# AE302F80F5582AE_CM55_HE_View register map
Vendor: Alif Semiconductor; Series: E3; File version: 1.0
CPU: CM55 r1p0, selectable endian, MPU, FPU, double-precision FPU, DSP, VTOR, 8 interrupt priority bits, 1 SAU regions
Registers are 32-bit, read-write, reset 0x0 unless marked. A register's access mark holds for its fields unless they carry their own. Offsets are from the block's base; [hi:lo] are bit positions; {n}, {i} and the like mark numbered series; <NAME> marks a mode.

## ETH (part 1 of 3)
Base 0x48100000
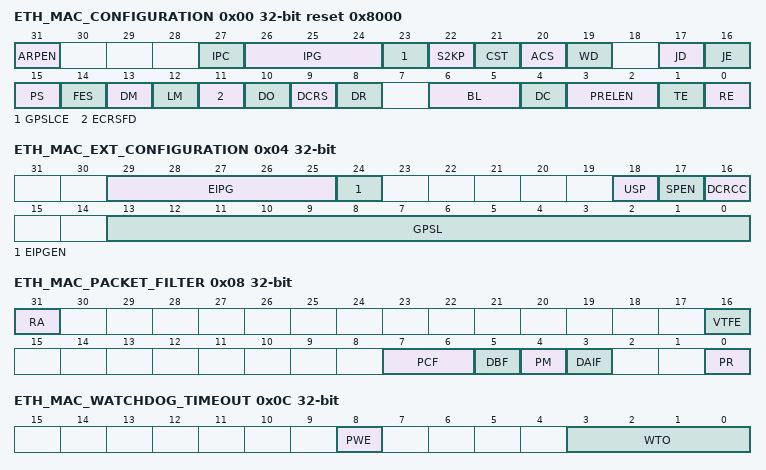
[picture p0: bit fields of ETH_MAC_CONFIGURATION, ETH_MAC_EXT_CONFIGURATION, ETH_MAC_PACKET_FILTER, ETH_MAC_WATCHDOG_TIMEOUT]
0x00 ETH_MAC_CONFIGURATION reset 0x8000 — MAC Configuration Register
  [31] ARPEN — ARP Offload Enable When this bit is set, the MAC can recognize an incoming ARP request packet and schedules the ARP packet for transmission. It forwards the ARP packet to the application and also indicate the events in the RxStatus. When this bit is reset, the MAC receiver does not recognize any ARP packet and indicates them as Type frame in the RxStatus. This bit is available only when the Enable IPv4 ARP Offload is selected.
    0=ARP offload is disabled; 1=ARP offload is enabled
  [27] IPC — Checksum Offload When set, this bit enables the IPv4 header checksum checking and IPv4 or IPv6 TCP, UDP, or ICMP payload checksum checking. When this bit is reset, the COE function in the receiver is disabled.
    0=IP header/payload checksum checking is disabled; 1=IP header/payload checksum checking is enabled
  [26:24] IPG — Inter-Packet Gap These bits control the minimum IPG between packets during transmission. This range of minimum IPG is valid in full-duplex mode. In the half-duplex mode, the minimum IPG can be configured only for 64-bit times (IPG = 100). Lower values are not considered. When a JAM pattern is being transmitted because of backpressure activation, the MAC does not consider the minimum IPG. This above function (IPG less than 96-bit times) is valid only when the ETH_MAC_EXT_CONFIGURATION[EIPGEN] bit is reset. When EIPGEN is set, then the minimum IPG (greater than 96-bit times) is controlled as per the description given in the ETH_MAC_EXT_CONFIGURATION[EIPG] field.
    0=96-bit times IPG; 1=88-bit times IPG; 2=80-bit times IPG; 3=72-bit times IPG; 4=64-bit times IPG; 5=56-bit times IPG; 6=48-bit times IPG; 7=40-bit times IPG
  [23] GPSLCE — Giant Packet Size Limit Control Enable When this bit is set, the MAC considers the value in the ETH_MAC_EXT_CONFIGURATION[GPSL] field to declare a received packet as Giant packet. This field must be programmed to more than 1,518 bytes. Otherwise, the MAC considers 1,518 bytes as giant packet limit. When this bit is reset, the MAC considers a received packet as Giant packet when its size is greater than 1,518 bytes (1522 bytes for tagged packet). The watchdog timeout limit, Jumbo Packet Enable and 2KB Packet Enable have higher precedence over this bit, that is the MAC considers a received packet as Giant packet when its size is greater than 9,018 bytes (9,022 bytes for tagged packet) with Jumbo Packet Enabled and greater than 2,000 bytes with 2KB Packet Enabled. The watchdog timeout, if enabled, terminates the received packet when watchdog limit is reached. Therefore, the programmed giant packet limit must be less than the watchdog limit to get the giant packet status.
    0=Giant packet size limit control is disabled; 1=Giant packet size limit control is enabled
  [22] S2KP — IEEE 802.3as Support for 2KB Packets When this bit is set, the MAC considers all packets with up to 2,000 bytes length as normal packets. When the JE bit is not set, the MAC considers all received packets of size more than 2KB as Giant packets. When this bit is reset and the JE bit is not set, the MAC considers all received packets of size more than 1,518 bytes (1,522 bytes for tagged) as giant packets. Note: When the JE bit is set, setting this bit has no effect on the giant packet status.
    0=Support upto 2KB packet is disabled; 1=Support upto 2KB packet is Enabled
  [21] CST — CRC stripping for Type packets When this bit is set, theMAC strips and drops the last four bytes (FCS) of all Ether type packets, as indicated by the Length/Type field of the packet, before forwarding the packet to the application
    0=CRC stripping for type packets is disabled; 1=CRC stripping for type packets is enabled
  [20] ACS — Automatic Pad or CRC Stripping When this bit is set, the MAC strips the Pad or FCS field on the incoming packets only if the value of the length field is less than 1,536 bytes. All received packets with length field greater than or equal to 1,536 bytes are passed to the application without stripping the Pad or FCS field. When this bit is reset, the MAC passes all incoming packets to the application, without any modification.
    0=Automatic Pad or CRC stripping is disabled; 1=Automatic Pad or CRC stripping is enabled
  [19] WD — Watchdog Disable When this bit is set, the MAC disables the watchdog timer on the receiver. The MAC can receive packets of up to 16,383 bytes. When this bit is reset, the MAC does not allow more than 2,048 bytes (10,240 if JE is set high) of the packet being received. The MAC cuts off any bytes received after 2,048 bytes.
    0=Watchdog is enabled; 1=Watchdog is disabled
  [17] JD — Jabber Disable When this bit is set, the MAC disables the jabber timer on the transmitter. The MAC can transfer packets of up to 16,383 bytes. When this bit is reset, if the application sends more than 2,048 bytes of data (10,240 if JE is set high) during transmission, the MAC does not send rest of the bytes in that packet.
    0=Jabber is enabled; 1=Jabber is disabled
  [16] JE — Jumbo Packet Enable When this bit is set, the MAC allows jumbo packets of 9,018 bytes (9,022 bytes for VLAN tagged packets) without reporting a giant packet error in the Rx packet status.
    0=Jumbo packet is disabled; 1=Jumbo packet is enabled
  [15] PS ro — Port Select This bit selects the Ethernet line speed. This bit, along with the FES bit, selects the exact line speed. Their value is also reflected in the ETH_STAT0[MAC_SPEED_O] field.
    1=For 10 or 100 Mbps operations
  [14] FES — Speed This bit selects the speed mode. Its value along with the PS bit value is also reflected in the ETH_STAT0[MAC_SPEED_O] field.
    0=10 Mbps; 1=100 Mbps
  [13] DM — Duplex Mode When this bit is set, the MAC operates in the full-duplex mode in which it can transmit and receive simultaneously.
    0=Half-duplex mode; 1=Full-duplex mode
  [12] LM — Loopback Mode When this bit is set, the MAC operates in the loopback mode at RMII.
    0=Loopback is disabled; 1=Loopback is enabled
  [11] ECRSFD — Enable Carrier Sense Before Transmission in Full-Duplex Mode When this bit is set, the MAC transmitter checks the ETH_CRS_DV signal before packet transmission in the full-duplex mode. The MAC starts the transmission only when the ETH_CRS_DV signal is low. When this bit is reset, the MAC transmitter ignores the status of the ETH_CRS_DV signal.
    0=ECRSFD is disabled; 1=ECRSFD is enabled
  [10] DO — Disable Receive Own When this bit is set, the MAC disables the reception of packets when the ETH_TXEN signal is asserted in the half-duplex mode. When this bit is reset, the MAC receives all packets given by the PHY. This bit is not applicable in the full-duplex mode.
    0=Enable receive own; 1=Disable receive own
  [9] DCRS — Disable Carrier Sense During Transmission When this bit is set, the MAC transmitter ignores the RMII ETH_CRS_DV signal during packet transmission in the half-duplex mode. As a result, no errors are generated because of Loss of Carrier or No Carrier during transmission. When this bit is reset, the MAC transmitter generates errors because of Carrier Sense. The MAC can even abort the transmission.
    0=Enable carrier sense during transmission; 1=Disable carrier sense during transmission
  [8] DR — Disable Retry When this bit is set, the MAC attempts only one transmission. When a collision occurs on the RMII interface, the MAC ignores the current packet transmission and reports a Packet Abort with excessive collision error in the Tx packet status. When this bit is reset, the MAC retries based on the settings of the BL field. This bit is applicable only in the half-duplex mode.
    0=Enable retry; 1=Disable retry
  [6:5] BL — Back-Off Limit The back-off limit determines the random integer number (r) of slot time delays (512-bit times) for which the MAC waits before rescheduling a transmission attempt during retries after a collision.n = retransmission attempt. The random integer r takes the value in the range 0 <= r < 2^k This bit is applicable only in the half-duplex mode.
    0=k = min(n, 10); 1=k = min(n, 8); 2=k = min(n, 4); 3=k = min(n, 1)
  [4] DC — Deferral Check When this bit is set, the deferral check function is enabled in the MAC. The MAC issues a Packet Abort status, along with the excessive deferral error bit set in the Tx packet status, when the Tx state machine is deferred for more than 24,288-bit times in 10 or 100 Mbps mode. The defer time is not cumulative. For example, if the transmitter defers for 10,000-bit times because the ETH_CRS_DV signal is active and the ETH_CRS_DV signal becomes inactive, the transmitter transmits and collision happens. Because of collision, the transmitter needs to back off and then defer again after back off completion. In such a scenario, the deferral timer is reset to 0, and it is restarted. When this bit is reset, the deferral check function is disabled and the MAC defers until the ETH_CRS_DV signal goes inactive. This bit is applicable only in the half-duplex mode.
    0=Deferral check function is disabled; 1=Deferral check function is enabled
  [3:2] PRELEN — Preamble Length for Transmit packets These bits control the number of preamble bytes that are added to the beginning of every Tx packet. The preamble reduction occurs only when the MAC is operating in the full-duplex mode.
    0=7 bytes of preamble; 1=5 bytes of preamble; 2=3 bytes of preamble
  [1] TE — Transmitter Enable When this bit is set, the Tx state machine of the MAC is enabled for transmission on the RMII interface. When this bit is reset, the MAC Tx state machine is disabled after it completes the transmission of the current packet. The Tx state machine does not transmit any more packets.
    0=Transmitter is disabled; 1=Transmitter is enabled
  [0] RE — Receiver Enable When this bit is set, the Rx state machine of the MAC is enabled for receiving packets from the RMII interface. When this bit is reset, the MAC Rx state machine is disabled after it completes the reception of the current packet. The Rx state machine does not receive any more packets from the RMII interface.
    0=Receiver is disabled; 1=Receiver is enabled
0x04 ETH_MAC_EXT_CONFIGURATION — MAC Extended Configuration Register
  [29:25] EIPG — Extended Inter-Packet Gap The value in this field is applicable when the EIPGEN bit is set. The five bits of this field are the most significant bits; the ETH_MAC_CONFIGURATION[IPG] field has the three least significant bits. Together, the eight bits represent the value of the minimum IPG greater than 96-bit times, in steps of 8-bit times: {EIPG, IPG}. 0x0: 104-bit times 0x1: 112-bit times 0x2: 120-bit times 0xFF: 2144-bit times
  [24] EIPGEN — Extended Inter-Packet Gap Enable When this bit is set, the MAC uses the EIPG field for the extended inter-packet gap. For details, see the description of the EIPG field. When this bit is reset, the MAC ignores the EIPG field and uses the ETH_MAC_CONFIGURATION[IPG] field as the minimum IPG less than or equal to 96-bit times, in steps of 8-bit times. Note: The extended Inter-Packet Gap feature must be enabled when operating in Full-Duplex mode only. There may be undesirable effects on back-pressure function and frame transmission if it is enabled in Half-Duplex mode.
    0=Extended inter-packet gap is disabled; 1=Extended inter-packet gap is enabled
  [18] USP — Unicast Slow Protocol Packet Detect When this bit is set, the MAC detects the Slow Protocol packets with unicast address of the station specified in the ETH_MAC_ADDRESS0_HIGH and ETH_MAC_ADDRESS0_LOW registers. The MAC also detects the Slow Protocol packets with the Slow Protocols multicast address (01-80-C2-00-00-02). When this bit is reset, the MAC detects only Slow Protocol packets with the Slow Protocol multicast address specified in the IEEE 802.3-2015 Specification, Section
    0=Unicast slow protocol packet detection is disabled; 1=Unicast slow protocol packet detection is enabled
  [17] SPEN — Slow Protocol Detection Enable When this bit is set, MAC processes the Slow Protocol packets (Ether Type 0x8809) and provides the Rx status. The MAC discards the Slow Protocol packets with invalid sub-types. When this bit is reset, the MAC forwards all the error-free Slow Protocol packets to the application. The MAC considers such packets as normal Type packets.
    0=Slow protocol detection is disabled; 1=Slow protocol detection is enabled
  [16] DCRCC — Disable CRC Checking for Received Packets When this bit is set, the MAC receiver does not check the CRC field in the received packets. When this bit is reset, the MAC receiver always checks the CRC field in the received packets.
    0=CRC checking is enabled; 1=CRC checking is disabled
  [13:0] GPSL — Giant Packet Size Limit If the received packet size is greater than the value programmed in this field in units of bytes, the MAC declares the received packet as Giant packet. The value programmed in this field must be greater than or equal to 1,518 bytes. Any other programmed value is considered as 1,518 bytes. For VLAN tagged packets, the MAC adds 4 bytes to the programmed value. When the Enable Double VLAN Processing option is selected, the MAC adds 8 bytes to the programmed value for double VLAN tagged packets. The value in this field is applicable when the GPSLCE bit is set in ETH_MAC_CONFIGURATION register.
0x08 ETH_MAC_PACKET_FILTER — MAC Packet Filter Register
  [31] RA — Receive All When this bit is set, the MAC Receiver module passes all received packets to the application, irrespective of whether they pass the address filter or not. The result of the SA or DA filtering is updated (pass or fail) in the corresponding bit in the Rx Status Word. When this bit is reset, the Receiver module passes only those packets to the application that pass the SA or DA address filter.
    0=Receive all is disabled; 1=Receive all is enabled
  [16] VTFE — VLAN Tag Filter Enable When this bit is set, the MAC drops the VLAN tagged packets that do not match the VLAN Tag. When this bit is reset, the MAC forwards all packets irrespective of the match status of the VLAN Tag.
    0=VLAN tag filter is disabled; 1=VLAN tag filter is enabled
  [7:6] PCF — Pass Control Packets These bits control the forwarding of all control packets (including unicast and multicast Pause packets).
    0=MAC filters all control packets from reaching the application; 1=MAC forwards all control packets except pause packets to the application even if they fail the address filter; 2=MAC forwards all control packets to the application even if they fail the address filter; 3=MAC forwards the control packets that pass the address filter
  [5] DBF — Disable Broadcast Packets When this bit is set, the AFM module blocks all incoming broadcast packets. In addition, it overrides all other filter settings. When this bit is reset, the AFM module passes all received broadcast packets.
    0=Enable broadcast packets; 1=Disable broadcast packets
  [4] PM — Pass All Multicast When this bit is set, it indicates that all the received packets with a multicast destination address (first bit in the destination address field is '1') are passed. When this bit is reset, filtering of multicast packet depends on HMC bit.
    0=Pass all multicast is disabled; 1=Pass all multicast is enabled
  [3] DAIF — DA Inverse Filtering When this bit is set, the Address Check block operates in inverse filtering mode for the DA address comparison for both unicast and multicast packets. When this bit is reset, normal filtering of packets is performed.
    0=DA inverse filtering is disabled; 1=DA inverse filtering is enabled
  [0] PR — Promiscuous Mode When this bit is set, the MAC transfers all incoming packets to the application regardless of the destination or source address filtering status. The MAC clears the SA or DA Filter Fail status bits of the MAC Rx Status Word. When this bit is reset, the MAC transfers to the application only the packets that pass destination or source address filtering.
    0=Promiscuous mode is disabled; 1=Promiscuous mode is enabled
0x0C ETH_MAC_WATCHDOG_TIMEOUT — Watchdog Timeout Register
  [8] PWE — Programmable Watchdog Enable When this bit is set and the ETH_MAC_CONFIGURATION[WD] bit is reset, the WTO field is used as watchdog timeout limit for a received packet. When this bit is cleared, the watchdog timeout for a received packet is controlled by setting of the ETH_MAC_CONFIGURATION[WD] and ETH_MAC_CONFIGURATION[JE] bits.
    0=Programmable watchdog is disabled; 1=Programmable watchdog is enabled
  [3:0] WTO — Watchdog Timeout When the PWE bit is set and the ETH_MAC_CONFIGURATION[WD] bit is reset, this field is used as watchdog timeout limit for a received packet. If the length of a received packet exceeds the value of this field, such packet is terminated and declared as an error packet. Note: When the PWE bit is set, the value in this field must be more than 1,522 (0x5F2). Otherwise, the IEEE 802.3-specified valid tagged packets are declared as error packets and then dropped.
    {v}={v+2}KB (v=0..13); 14=16383 bytes
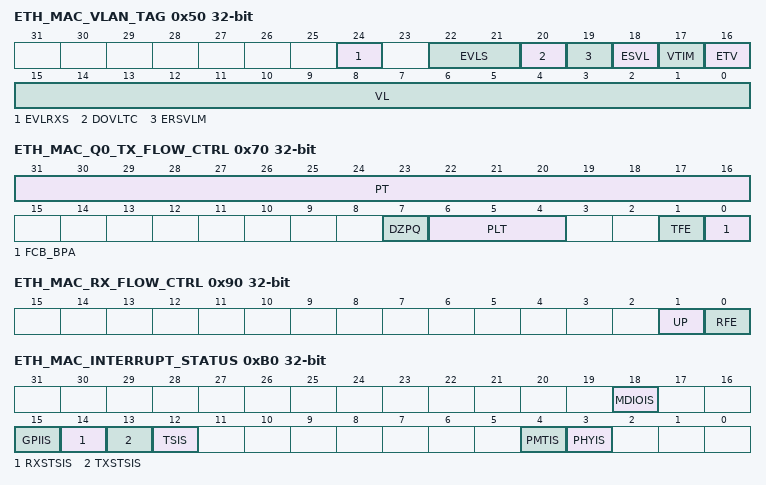
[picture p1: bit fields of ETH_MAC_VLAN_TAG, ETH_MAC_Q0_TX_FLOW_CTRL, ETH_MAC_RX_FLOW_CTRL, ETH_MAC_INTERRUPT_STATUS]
0x50 ETH_MAC_VLAN_TAG — VLAN Tag Register
  [24] EVLRXS — Enable VLAN Tag in Rx status When this bit is set, MAC provides the outer VLAN Tag in the Rx status. When this bit is reset, the MAC does not provide the outer VLAN Tag in Rx status.
    0=VLAN tag in Rx status is disabled; 1=VLAN tag in Rx status is enabled
  [22:21] EVLS — Enable VLAN Tag Stripping on Receive This field indicates the stripping operation on the outer VLAN Tag in the received packet.
    0=Do not strip; 1=Strip if VLAN filter passes; 2=Strip if VLAN filter fails; 3=Always strip
  [20] DOVLTC — Disable VLAN Type Check When this bit is set, the MAC does not check whether the VLAN Tag specified by the ERIVLT bit is of type S-VLAN or C-VLAN. When this bit is reset, the MAC filters or matches the VLAN Tag specified by the ERIVLT bit only when VLAN Tag type is similar to the one specified by the ERSVLM bit. The VLAN filter is bypassed when VLAN Type of received packet do not match the programmed VLAN Type in the VLAN filter.
    0=VLAN type check is enabled; 1=VLAN type check is disabled
  [19] ERSVLM — Enable Receive S-VLAN Match When this bit is set, the MAC receiver enables filtering or matching for S-VLAN (Type = 0x88A8) packets. When this bit is reset, the MAC receiver enables filtering or matching for C-VLAN (Type = 0x8100) packets. The ERIVLT bit determines the VLAN tag position considered for filtering or matching.
    0=Receive S-VLAN match is disabled; 1=Receive S-VLAN match is enabled
  [18] ESVL — Enable S-VLAN When this bit is set, the MAC transmitter and receiver consider the S-VLAN packets (Type = 0x88A8) as valid VLAN tagged packets.
    0=S-VLAN is disabled; 1=S-VLAN is enabled
  [17] VTIM — VLAN Tag Inverse Match Enable When this bit is set, this bit enables the VLAN Tag inverse matching. The packets without matching VLAN Tag are marked as matched. When reset, this bit enables the VLAN Tag perfect matching. The packets with matched VLAN Tag are marked as matched.
    0=VLAN tag inverse match is disabled; 1=VLAN tag inverse match is enabled
  [16] ETV — Enable 12-Bit VLAN Tag Comparison When this bit is set, a 12-bit VLAN identifier is used for comparing and filtering instead of the complete 16-bit VLAN tag. Bits[11-0] of the VLAN tag are compared with the corresponding field in the received VLAN-tagged packet. Similarly, when enabled, only 12 bits of the VLAN tag in the received packet are used for hash-based VLAN filtering. When this bit is reset, all 16 bits of the 15th and 16th bytes of the received VLAN packet are used for comparison and VLAN hash filtering.
    0=12-Bit VLAN tag comparison is disabled; 1=12-Bit VLAN tag comparison is enabled
  [15:0] VL — VLAN Tag Identifier for Receive Packets This field contains the 802.1Q VLAN tag to identify the VLAN packets. This VLAN tag identifier is compared to the 15th and 16th bytes of the packets being received for VLAN packets. The following list describes the bits of this field: Bits[15-13]: User Priority Bit 12: Canonical Format Indicator (CFI) or Drop Eligible Indicator (DEI) Bits[11-0]: VLAN Identifier (VID) field of VLAN tag If this field ([11-0] if ETV is set) is all zeros, the MAC does not check the 15th and 16th bytes for VLAN tag comparison and declares all packets with Type field value of 0x8100 or 0x88A8 as VLAN packets.
0x70 ETH_MAC_Q0_TX_FLOW_CTRL — Flow Control Register
  [31:16] PT — Pause Time This field holds the value to be used in the Pause Time field in the Tx control packet. If the Pause Time bits are configured to be double-synchronized to the RMII clock domain, consecutive writes to this register must be performed only after at least four clock cycles in the destination clock domain.
  [7] DZPQ — Disable Zero-Quanta Pause When this bit is set, it disables the automatic generation of the zero-quanta Pause packets. When this bit is reset, normal operation with automatic zero-quanta Pause packet generation is enabled.
    0=Zero-quanta pause packet generation is enabled; 1=Zero-quanta pause packet generation is disabled
  [6:4] PLT — Pause Low Threshold This field configures the automatic retransmission interval of the Pause packet. The value must always be less than the Pause Time configured in the PT field. For example, if PT = 0x100 (256 slot times), and PLT = 0x1, a second Pause packet is automatically transmitted at 228 (256-28) slot times after the first Pause packet is transmitted. The following list provides the threshold values for different values.The slot time is defined as the time taken to transmit 512 bits (64 bytes) on the RMII interface. This (approximate) computation is based on the packet size (64, 1518, 2000, 9018, 16384, or 32768) + 2 Pause Packet Size + IPG in Slot Times.
    0=Pause time minus 4 slot times (PT - 4 slot times); 1=Pause time minus 28 slot times (PT - 28 slot times); 2=Pause time minus 36 slot times (PT - 36 slot times); 3=Pause time minus 144 slot times (PT - 144 slot times); 4=Pause time minus 256 slot times (PT - 256 slot times); 5=Pause time minus 512 slot times (PT - 512 slot times)
  [1] TFE — Transmit Flow Control Enable Full-Duplex Mode: In the full-duplex mode, when this bit is set, the MAC enables the flow control operation to Tx Pause packets. When this bit is reset, the flow control operation in the MAC is disabled, and the MAC does not transmit any Pause packets. Half-Duplex Mode: In the half-duplex mode, when this bit is set, the MAC enables the backpressure operation. When this bit is reset, the backpressure feature is disabled.
    0=Transmit flow control is disabled; 1=Transmit flow control is enabled
  [0] FCB_BPA — Flow Control Busy or Backpressure Activate This bit initiates a Pause packet in the full-duplex mode and activates the backpressure function in the half-duplex mode if the TFE bit is set. Full-Duplex Mode: In the full-duplex mode, this bit must be read as 0x0 before writing to this register. To initiate a Pause packet, the application must set this bit to 0x1. During Control packet transfer, this bit continues to be set to indicate that a packet transmission is in progress. When Pause packet transmission is complete, the MAC resets this bit to 0x0. The user must not write to this register until this bit is cleared. Half-Duplex Mode: When this bit is set (and TFE bit is set) in the half-duplex mode, the MAC asserts the backpressure. During backpressure, when the MAC receives a new packet, the transmitter starts sending a JAM pattern resulting in a collision. Access restriction applies. - MAC initiates the pause packet or activates the backpressure, when application writes 1. - MAC writes 0 after the operation is complete. - MAC ignores when application writes 0.
    0=Flow control busy or backpressure activate is disabled; 1=Flow control busy or backpressure activate is enabled
0x90 ETH_MAC_RX_FLOW_CTRL — Receive Flow Control Register
  [1] UP — Unicast Pause Packet Detect A pause packet is processed when it has the unique multicast address specified in the IEEE 802.3 Specification. When this bit is set, the MAC can also detect Pause packets with unicast address of the station. This unicast address must be as specified in ETH_MAC_ADDRESS0_HIGH and ETH_MAC_ADDRESS0_LOW. When this bit is reset, the MAC only detects Pause packets with unique multicast address. Note: The MAC does not process a Pause packet if the multicast address is different from the unique multicast address. This is also applicable to the received PFC packet when the Priority Flow Control (PFC) is enabled. The unique multicast address (0x1_80_C2_00_00_01) is as specified in the IEEE 802.1 Qbb-2011 Specification.
    0=Unicast pause packet detect disabled; 1=Unicast pause packet detect enabled
  [0] RFE — Receive Flow Control Enable When this bit is set and the MAC is operating in full-duplex mode, the MAC decodes the received Pause packet and disables its transmitter for a specified (Pause) time. When this bit is reset or the MAC is operating in half-duplex mode, the decode function of the Pause packet is disabled. When PFC is enabled, flow control is enabled for PFC packets. The MAC decodes the received PFC packet and disables the Transmit queue, with matching priorities, for a duration of received Pause time.
    0=Receive flow control is disabled; 1=Receive flow control is enabled
0xB0 ETH_MAC_INTERRUPT_STATUS ro — Interrupt Status Register
  [18] MDIOIS — MDIO Interrupt Status When set, this bit indicates to the application that MDIO operation is complete. MAC writes 0 to this bit when the application reads this bit. Application can write 1 to clear this bit when ETH_MAC_CSR_SW_CTRL[RCWE] = 1. Following access restrictions apply: - Clears on read - Clears on write 1, when ETH_MAC_CSR_SW_CTRL[RCWE] = 1 - Self-set to 1 on internal event
    0=MDIO interrupt status not active; 1=MDIO interrupt status active
  [15] GPIIS — GPI Interrupt Status This bit is set when any active event (LL or LH) occurs on the ETH_MAC_GPIO_STATUS[GPIS] field and the corresponding bit is enabled in the ETH_MAC_GPIO_CONTROL[GPIE] field. This bit is cleared on reading the ETH_MAC_GPIO_STATUS[GPIS] field.
    0=GPI Interrupt status not active; 1=GPI Interrupt status active
  [14] RXSTSIS — Receive Status Interrupt This bit indicates the status of received packets. This bit is set when the RWT bit is set in the ETH_MAC_RX_TX_STATUS register. This bit is cleared when the corresponding interrupt source bit is read (or corresponding interrupt source bit is written to 1 when the ETH_MAC_CSR_SW_CTRL[RCWE] bit is set) in the ETH_MAC_RX_TX_STATUS register.
    0=Receive interrupt status not active; 1=Receive interrupt status active
  [13] TXSTSIS — Transmit Status Interrupt This bit indicates the status of transmitted packets. This bit is set when any of the following bits is set: - ETH_MAC_RX_TX_STATUS[EXCOL] - ETH_MAC_RX_TX_STATUS[LCOL] - ETH_MAC_RX_TX_STATUS[EXDEF] - ETH_MAC_RX_TX_STATUS[LCARR] - ETH_MAC_RX_TX_STATUS[NCARR] - ETH_MAC_RX_TX_STATUS[TJT]
    0=Transmit interrupt status not active; 1=Transmit interrupt status active
  [12] TSIS — Timestamp Interrupt Status This bit is set when any of the following conditions is true: - The ETH_MAC_TIMESTAMP_STATUS[TSTRGTERR0] bit is set. - The ETH_MAC_TIMESTAMP_STATUS[TSTARGT0] bit is set. - The ETH_MAC_TIMESTAMP_STATUS[TSSOVF] bit is set. - When drop transmit status is enabled in MTL, this bit is set when the captured transmit timestamp is updated in the ETH_MAC_TX_TIMESTAMP_STATUS_NANOSECONDS and ETH_MAC_TX_TIMESTAMP_STATUS_SECONDS registers. This bit is cleared when the corresponding interrupt source bit is read in the ETH_MAC_TIMESTAMP_STATUS register or the corresponding interrupt source bit is written to 1 when the ETH_MAC_CSR_SW_CTRL[RCWE] bit is set.
    0=Timestamp interrupt status not active; 1=Timestamp interrupt status active
  [4] PMTIS — PMT Interrupt Status This bit is set when a Magic packet or Wake-on-LAN packet is received in the power-down mode (the ETH_MAC_PMT_CONTROL_STATUS[RWKPRCVD] and ETH_MAC_PMT_CONTROL_STATUS[MGKPRCVD] bits). This bit is cleared when corresponding interrupt source bit are cleared because of a Read operation to the ETH_MAC_PMT_CONTROL_STATUS register (or corresponding interrupt source bit of ETH_MAC_PMT_CONTROL_STATUS register is written to 1 when the ETH_MAC_CSR_SW_CTRL[RCWE] bit is set).
    0=PMT interrupt status not active; 1=PMT interrupt status active
  [3] PHYIS — PHY Interrupt This bit is set when rising edge is detected on the ETH_IRQ input. This bit is cleared when this register is read (or this bit is written to 1 when the ETH_MAC_CSR_SW_CTRL[RCWE] bit is set).
    0=PHY interrupt not detected; 1=PHY interrupt detected
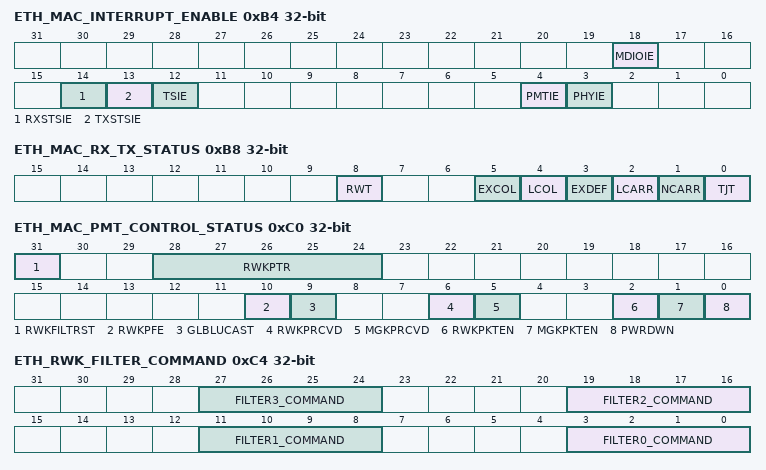
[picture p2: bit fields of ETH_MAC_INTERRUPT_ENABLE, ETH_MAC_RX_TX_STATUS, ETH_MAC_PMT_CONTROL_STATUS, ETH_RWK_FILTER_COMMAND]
0xB4 ETH_MAC_INTERRUPT_ENABLE — Interrupt Enable Register
  [18] MDIOIE — MDIO Interrupt Enable When this bit is set, it enables the assertion of the interrupt when the ETH_MAC_INTERRUPT_STATUS[MDIOIS] bit is set.
    0=MDIO interrupt is disabled; 1=MDIO interrupt is enabled
  [14] RXSTSIE — Receive Status Interrupt Enable When this bit is set, it enables the assertion of the interrupt signal because of the setting of the ETH_MAC_INTERRUPT_STATUS[RXSTSIS] bit.
    0=Receive status interrupt is disabled; 1=Receive status interrupt is enabled
  [13] TXSTSIE — Transmit Status Interrupt Enable When this bit is set, it enables the assertion of the interrupt signal because of the setting of the ETH_MAC_INTERRUPT_STATUS[TXSTSIS] bit.
    0=Transmit status interrupt is disabled; 1=Transmit status interrupt is enabled
  [12] TSIE — Timestamp Interrupt Enable When this bit is set, it enables the assertion of the interrupt signal because of the setting of the ETH_MAC_INTERRUPT_STATUS[TSIS] bit.
    0=Timestamp interrupt is disabled; 1=Timestamp interrupt is enabled
  [4] PMTIE — PMT Interrupt Enable When this bit is set, it enables the assertion of the interrupt signal because of the setting of the ETH_MAC_INTERRUPT_STATUS[PMTIS] bit.
    0=PMT interrupt is disabled; 1=PMT interrupt is enabled
  [3] PHYIE — PHY Interrupt Enable When this bit is set, it enables the assertion of the interrupt signal because of the setting of the ETH_MAC_INTERRUPT_STATUS[PHYIS] bit.
    0=PHY interrupt is disabled; 1=PHY interrupt is enabled
0xB8 ETH_MAC_RX_TX_STATUS ro — Receive Transmit Status Register
  [8] RWT — Receive Watchdog Timeout This bit is set when a packet with length greater than 2,048 bytes is received (10, 240 bytes when Jumbo Packet mode is enabled) and the ETH_MAC_CONFIGURATION[WD] bit is reset. This bit is also set when a packet with length greater than 16,383 bytes is received and the ETH_MAC_CONFIGURATION[WD] bit is set. Access restriction applies. Clears on read (or write of 1 when the ETH_MAC_CSR_SW_CTRL[RCWE] bit is set). Self-set to 1 on internal event.
    0=No receive watchdog timeout; 1=Receive watchdog timed out
  [5] EXCOL — Excessive Collisions When the ETH_MTL_OPERATION_MODE[DTXSTS] bit is set, this bit indicates that the transmission aborted after 16 successive collisions while attempting to transmit the current packet. If the DR bit is set in the ETH_MAC_CONFIGURATION register, this bit is set after the first collision and the packet transmission is aborted. Access restriction applies. Clears on read (or write of 1 when the ETH_MAC_CSR_SW_CTRL[RCWE] bit is set). Self-set to 1 on internal event.
    0=No collision; 1=Excessive collision is sensed
  [4] LCOL — Late Collision When the ETH_MTL_OPERATION_MODE[DTXSTS] bit is set, this bit indicates that the packet transmission aborted because a collision occurred after the collision window (64 bytes including preamble). This bit is not valid if the Underflow error occurs. Access restriction applies. Clears on read (or write of 1 when the ETH_MAC_CSR_SW_CTRL[RCWE] bit is set). Self-set to 1 on internal event.
    0=No collision; 1=Late collision is sensed
  [3] EXDEF — Excessive Deferral When the ETH_MTL_OPERATION_MODE[DTXSTS] bit is set and the DC bit is set in the ETH_MAC_CONFIGURATION register, this bit indicates that the transmission ended because of excessive deferral of over 24,288-bit times (155,680 when Jumbo packet is enabled). Access restriction applies. Clears on read (or write of 1 when the ETH_MAC_CSR_SW_CTRL[RCWE] bit is set). Self-set to 1 on internal event.
    0=No excessive deferral; 1=Excessive deferral
  [2] LCARR — Loss of Carrier When the ETH_MTL_OPERATION_MODE[DTXSTS] bit is set, this bit indicates that the loss of carrier occurred during packet transmission, that is, the ETH_CRS_DV signal was inactive for one or more transmission clock periods during packet transmission. This bit is valid only for packets transmitted without collision. Access restriction applies. Clears on read (or write of 1 when the ETH_MAC_CSR_SW_CTRL[RCWE] bit is set). Self-set to 1 on internal event.
    0=Carrier is present; 1=Loss of carrier
  [1] NCARR — No Carrier When the ETH_MTL_OPERATION_MODE[DTXSTS] bit is set, this bit indicates that the carrier signal from the PHY is not present at the end of preamble transmission. Access restriction applies. Clears on read (or write of 1 when the ETH_MAC_CSR_SW_CTRL[RCWE] bit is set). Self-set to 1 on internal event.
    0=Carrier is present; 1=No carrier
  [0] TJT — Transmit Jabber Timeout This bit indicates that the Transmit Jabber Timer expired which happens when the packet size exceeds 2,048 bytes (10,240 bytes when the Jumbo packet is enabled) and JD bit is reset in the ETH_MAC_CONFIGURATION register. This bit is set when the packet size exceeds 16,383 bytes and the JD bit is set in the ETH_MAC_CONFIGURATION register. Access restriction applies. Clears on read (or write of 1 when the ETH_MAC_CSR_SW_CTRL[RCWE] bit is set). Self-set to 1 on internal event.
    0=No transmit jabber timeout; 1=Transmit jabber timeout occurred
0xC0 ETH_MAC_PMT_CONTROL_STATUS — PMT Control and Status Register
  [31] RWKFILTRST — Remote Wake-Up Packet Filter Register Pointer Reset When this bit is set, the remote wake-up packet filter register pointer is reset to 0x0. It is automatically cleared after 1 clock cycle. Access restriction applies. Setting 1 sets. Self-cleared. Setting 0 has no effect.
    0=Remote wake-up packet filter register pointer is not reset; 1=Remote wake-up packet filter register pointer is reset
  [28:24] RWKPTR ro — Remote Wake-up FIFO Pointer This field gives the current value of the Remote Wake-up Packet Filter register pointer.
  [10] RWKPFE — Remote Wake-up Packet Forwarding Enable When this bit is set along with RWKPKTEN, the MAC receiver drops all received frames until it receives the expected wake-up frame. All frames after that event including the received wake-up frame are forwarded to application. This bit is then self-cleared on receiving the wake-up packet. The application can also clear this bit before the expected wake-up frame is received. In such cases, the MAC reverts to the default behavior where packets received are forwarded to the application. This bit must only be set when RWKPKTEN is set high and PWRDWN is set low. The setting of this bit has no effect when PWRDWN is set high. Note: If Magic Packet Enable and Wake-Up Frame Enable are both set along with setting of this bit and Magic Packet is received prior to wake-up frame, this bit is self-cleared on receiving Magic Packet, the received Magic packet is dropped, and all frames after received Magic Packet are forwarded to application. Access restriction applies. Setting 1 sets. Self-cleared. Setting 0 has no effect.
    0=Remote wake-up packet forwarding is disabled; 1=Remote wake-up packet forwarding is enabled
  [9] GLBLUCAST — Global Unicast When this bit set, any unicast packet filtered by the MAC (DAF) address recognition is detected as a remote wake-up packet.
    0=Global unicast is disabled; 1=Global unicast is enabled
  [6] RWKPRCVD ro — Remote Wake-Up Packet Received When this bit is set, it indicates that the power management event is generated because of the reception of a remote wake-up packet. This bit is cleared when this register is read. Access restriction applies. Clears on read or write of 1 when the ETH_MAC_CSR_SW_CTRL[RCWE] bit is set. Self-set to 1 on internal event.
    0=Remote wake-up packet is received; 1=Remote wake-up packet is received
  [5] MGKPRCVD ro — Magic Packet Received When this bit is set, it indicates that the power management event is generated because of the reception of a magic packet. This bit is cleared when this register is read. Access restriction applies. Clears on read or write of 1 when the ETH_MAC_CSR_SW_CTRL[RCWE] bit is set. Self-set to 1 on internal event.
    0=No magic packet is received; 1=Magic packet is received
  [2] RWKPKTEN — Remote Wake-Up Packet Enable When this bit is set, a power management event is generated when the MAC receives a remote wake-up packet.
    0=Remote wake-up packet is disabled; 1=Remote wake-up packet is enabled
  [1] MGKPKTEN — Magic Packet Enable When this bit is set, a power management event is generated when the MAC receives a magic packet.
    0=Magic packet is disabled; 1=Magic packet is enabled
  [0] PWRDWN — Power Down When this bit is set, the MAC receiver drops all received packets until it receives the expected magic packet or remote wake-up packet. This bit is then self-cleared and the power-down mode is disabled. The software can clear this bit before the expected magic packet or remote wake-up packet is received. The packets received by the MAC after this bit is cleared are forwarded to the application. This bit must only be set when the MGKPKTEN, GLBLUCAST, or RWKPKTEN bit is set high. Note: The user can gate-off the CLK_CSR during power-down mode. However, when the CLK_CSR is gated-off, the user cannot perform any read or write operations on this register. Therefore, software cannot clear this bit. Access restriction applies. Setting 1 sets. Self-cleared. Setting 0 has no effect.
    0=Power down is disabled; 1=Power down is enabled
0xC4 ETH_RWK_FILTER_BYTE_MASK — Remote Wakeup Filter Byte Mask Register
  [31:0] FILTER_BYTE_MASK — Filter0 to Filter3 32-bit Mask This field defines the bytes of the packet that are examined by the corresponding filter (0 to 3) to determine whether or not a packet is a wake-up packet. Bit 31 must be zero. Bits [30-0] are the byte mask. Each bit in this mask corresponds to one byte in the detected packet. If the bit is 1, the corresponding byte is taken into the CRC16 calculation.
0xC4 ETH_RWK_FILTER_COMMAND (alternate view of ETH_RWK_FILTER_BYTE_MASK) — Remote Wakeup Filter Command Register
  [8n+3:8n] FILTER{n}_COMMAND (n=0..3) — Filter{n} Command The 4-bit filter command controls the filter operation. Bit {8n+3} specifies the address type, defining the destination address type of the pattern. When the bit is set, the pattern applies to only multicast packets; when the bit is reset, the pattern applies only to unicast packet. Bit {8n+2} (Inverse Mode), when set, reverses the logic of the CRC16 hash function signal, to reject a packet with matching CRC_16 value. Bit {8n+2}, along with Bit {8n+1}, allows a MAC to reject a subset of remote wake-up packets by creating filter logic such as Pattern 1 AND NOT Pattern 2. Bit {8n+1} (And_Previous) implements the Boolean logic. When set, the result of the current entry is logically ANDed with the result of the previous filter. This AND logic allows a filter pattern longer than 32 bytes by splitting the mask among two, three, or four filters. This depends on the number of filters that have the And_Previous bit set. Bit {8n} is the enable for filter. If Bit {8n} is not set, filter is disabled.
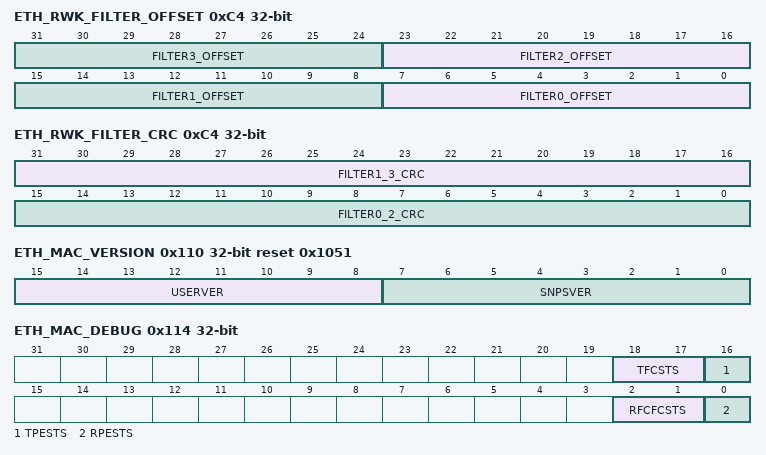
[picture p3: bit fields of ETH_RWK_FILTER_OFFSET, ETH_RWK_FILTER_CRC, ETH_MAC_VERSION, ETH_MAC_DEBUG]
0xC4 ETH_RWK_FILTER_OFFSET (alternate view of ETH_RWK_FILTER_BYTE_MASK) — Remote Wakeup Filter Offset Register
  [8n+7:8n] FILTER{n}_OFFSET (n=0..3) — Filter{n} Offset This filter offset defines the offset (within the packet) from which the filter examines the packets. This 8-bit pattern-offset is the offset for the filter first byte to be examined. The minimum allowed offset is 12, which refers to the 13th byte of the packet. The offset value 0 refers to the first byte of the packet.
0xC4 ETH_RWK_FILTER_CRC (alternate view of ETH_RWK_FILTER_BYTE_MASK) — Remote Wakeup Filter CRC-16 Register
  [31:16] FILTER1_3_CRC — Filter1 and Filter3 CRC-16 This field contains the CRC_16 value calculated from the pattern and also the byte mask programmed to the wake-up filter register block. The 16-bit CRC calculation uses the following polynomial: G(x) = x^16 + x^15 + x^2 + 1 Each mask, used in the hash function calculation, is compared with a 16-bit value associated with that mask. Each filter has the following: - 32-bit mask: Each bit in this mask corresponds to one byte in the detected packet. If the bit is 1, the corresponding byte is taken into the CRC-16 calculation. - 8-bit offset pointer: Specifies the byte to start the CRC-16 computation. The pointer and the mask are used together to locate the bytes to be used in the CRC-16 calculations.
  [15:0] FILTER0_2_CRC — Filter0 and Filter2 CRC-16 This field contains the CRC_16 value calculated from the pattern and also the byte mask programmed to the wake-up filter register block. The 16-bit CRC calculation uses the following polynomial: G(x) = x^16 + x^15 + x^2 + 1 Each mask, used in the hash function calculation, is compared with a 16-bit value associated with that mask. Each filter has the following: - 32-bit mask: Each bit in this mask corresponds to one byte in the detected packet. If the bit is 1, the corresponding byte is taken into the CRC-16 calculation. - 8-bit offset pointer: Specifies the byte to start the CRC-16 computation. The pointer and the mask are used together to locate the bytes to be used in the CRC-16 calculations.
0x110 ETH_MAC_VERSION ro reset 0x1051 — Module Version Register
  [15:8] USERVER — User-defined version
  [7:0] SNPSVER — Vendor-defined version
0x114 ETH_MAC_DEBUG ro — Debug Register
  [18:17] TFCSTS — Reserved
  [16] TPESTS — MAC RMII Transmit Protocol Engine Status When this bit is set, it indicates that the MAC RMII transmit protocol engine is actively transmitting data, and it is not in the Idle state.
    0=MAC RMII transmit protocol engine status not detected; 1=MAC RMII transmit protocol engine status detected
  [2:1] RFCFCSTS — Reserved
  [0] RPESTS — MAC RMII Receive Protocol Engine Status When this bit is set, it indicates that the MAC RMII receive protocol engine is actively receiving data, and it is not in the Idle state.
    0=MAC RMII receive protocol engine status not detected; 1=MAC RMII receive protocol engine status detected
